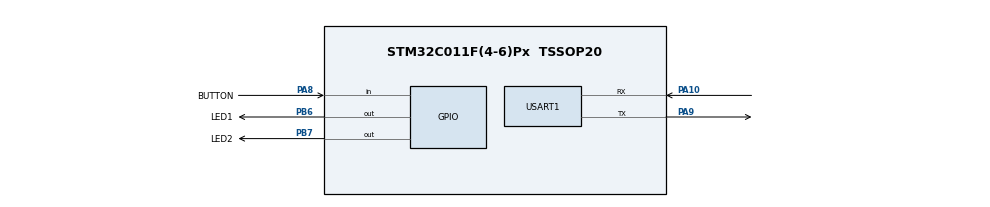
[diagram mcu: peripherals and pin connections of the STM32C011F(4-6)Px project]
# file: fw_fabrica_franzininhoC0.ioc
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Mcu.Family=STM32C0
Mcu.Name=STM32C011F(4-6)Px
Mcu.Package=TSSOP20
PA10\ [PA12].Mode=Asynchronous
PA10\ [PA12].Signal=USART1_RX
PA13.Mode=Serial_Wire
PA13.Signal=DEBUG_SWDIO
PA14-BOOT0.Mode=Serial_Wire
PA14-BOOT0.Signal=DEBUG_SWCLK
PA8.GPIO_Label=BUTTON
PA8.GPIO_PuPd=GPIO_PULLUP
PA8.Signal=GPIO_Input
PA9\ [PA11].Mode=Asynchronous
PA9\ [PA11].Signal=USART1_TX
PB6.GPIO_Label=LED1
PB6.Signal=GPIO_Output
PB7.GPIO_Label=LED2
PB7.Signal=GPIO_Output
ProjectManager.HeapSize=0x200
ProjectManager.StackSize=0x400
ProjectManager.TargetToolchain=STM32CubeIDE
RCC.ADCFreq_Value=12000000
RCC.AHBFreq_Value=12000000
RCC.CortexFreq_Value=12000000
RCC.EXTERNAL_CLOCK_VALUE=12288000
RCC.HCLKFreq_Value=12000000
RCC.HSE_VALUE=8000000
RCC.HSI_VALUE=48000000
RCC.LSE_VALUE=32768
RCC.SYSCLKFreq_VALUE=12000000
USART1.VirtualMode-Asynchronous=VM_ASYNC
VP_SYS_VS_PINREMAP.Mode=PINREMAP
VP_SYS_VS_PINREMAP_10_12.Mode=PINREMAP_10_12
board=custom

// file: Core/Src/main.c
/* USER CODE BEGIN Header */
/**
  ******************************************************************************
  * @file           : main.c
  * @brief          : Main program body
  ******************************************************************************
  * @attention
  *
  * Copyright (c) 2023 STMicroelectronics.
  * All rights reserved.
  *
  * This software is licensed under terms that can be found in the LICENSE file
  * in the root directory of this software component.
  * If no LICENSE file comes with this software, it is provided AS-IS.
  *
  ******************************************************************************
  */
/* USER CODE END Header */
#include "main.h"
#include "usart.h"
#include "gpio.h"

void SystemClock_Config(void);

int main(void)
{

  /* MCU Configuration--------------------------------------------------------*/

  /* Reset of all peripherals, Initializes the Flash interface and the Systick. */
  HAL_Init();

  /* Configure the system clock */
  SystemClock_Config();

  /* Initialize all configured peripherals */
  MX_GPIO_Init();
  MX_USART1_UART_Init();
  /* USER CODE BEGIN 2 */
  const uint8_t msg[] = "Franzininho C0\r\nSaiba mais em: docs.franzininho.com.br\r\n";
  uint16_t i = 0;
  /* USER CODE END 2 */

  /* Infinite loop */
  /* USER CODE BEGIN WHILE */
  while (1)
  {
	HAL_Delay(100);			//delay 100 ms
	i++;
	if(i>=10)
	{
	 i= 0; //reinicia contador
	 HAL_GPIO_TogglePin(LED1_GPIO_Port, LED1_Pin);	//inverte LED1
	 HAL_UART_Transmit(&huart1,msg, sizeof(msg)-1,100); //envia mensagem na serial
	}
	if(!HAL_GPIO_ReadPin(BUTTON_GPIO_Port, BUTTON_Pin)) //se botão pressionado
	{
		HAL_GPIO_WritePin(LED2_GPIO_Port, LED2_Pin,1);	//liga LED2
	}
	else
	{
		HAL_GPIO_WritePin(LED2_GPIO_Port, LED2_Pin,0);	//liga LED2
	}

    /* USER CODE END WHILE */

  }
}

void SystemClock_Config(void)
{
  RCC_OscInitTypeDef RCC_OscInitStruct = {0};
  RCC_ClkInitTypeDef RCC_ClkInitStruct = {0};

  /** Initializes the RCC Oscillators according to the specified parameters
  * in the RCC_OscInitTypeDef structure.
  */
  RCC_OscInitStruct.OscillatorType = RCC_OSCILLATORTYPE_HSI;
  RCC_OscInitStruct.HSIState = RCC_HSI_ON;
  RCC_OscInitStruct.HSIDiv = RCC_HSI_DIV4;
  RCC_OscInitStruct.HSICalibrationValue = RCC_HSICALIBRATION_DEFAULT;
  if (HAL_RCC_OscConfig(&RCC_OscInitStruct) != HAL_OK)
  {
    Error_Handler();
  }

  /** Initializes the CPU, AHB and APB buses clocks
  */
  RCC_ClkInitStruct.ClockType = RCC_CLOCKTYPE_HCLK|RCC_CLOCKTYPE_SYSCLK
                              |RCC_CLOCKTYPE_PCLK1;
  RCC_ClkInitStruct.SYSCLKSource = RCC_SYSCLKSOURCE_HSI;
  RCC_ClkInitStruct.SYSCLKDivider = RCC_SYSCLK_DIV1;
  RCC_ClkInitStruct.AHBCLKDivider = RCC_HCLK_DIV1;
  RCC_ClkInitStruct.APB1CLKDivider = RCC_APB1_DIV1;

  if (HAL_RCC_ClockConfig(&RCC_ClkInitStruct, FLASH_LATENCY_0) != HAL_OK)
  {
    Error_Handler();
  }
}

void Error_Handler(void)
{
  __disable_irq();
  while (1)
  {
  }
}
